# XMC4300 register map
Vendor: Infineon; File version: 0.5.1 (Superset device XMC4800)
CPU: CM4 r2p0, little endian, MPU, FPU, 6 interrupt priority bits
Registers are 32-bit, read-write, reset 0x0 unless marked. A register's access mark holds for its fields unless they carry their own. Offsets are from the block's base; [hi:lo] are bit positions; {n}, {i} and the like mark numbered series; 'fields as' and 'values as' point back to an identical list.

## SCU_POWER — System Control Unit
Base 0x50004200
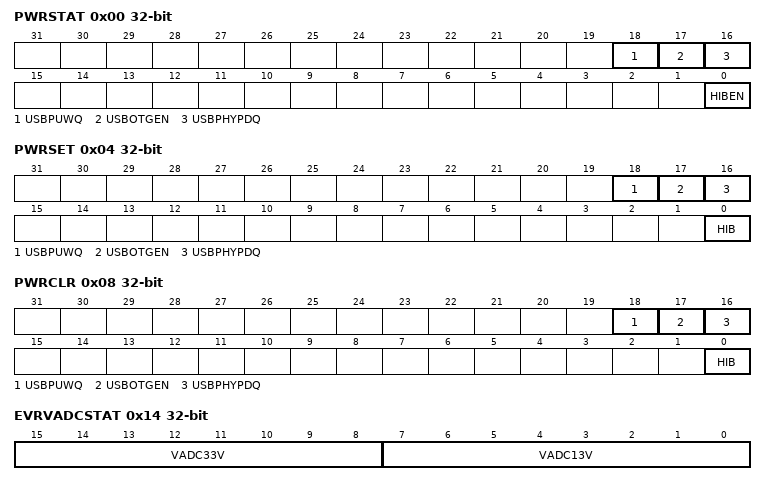
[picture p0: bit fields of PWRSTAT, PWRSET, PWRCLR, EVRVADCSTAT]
0x00 PWRSTAT ro — PCU Status Register
  [18] USBPUWQ — USB Weak Pull-Up at PADN State
    0=Pull-up active; 1=Pull-up not active
  [17] USBOTGEN — USB On-The-Go Comparators State
    0=Power-down; 1=Active
  [16] USBPHYPDQ — USB PHY Transceiver State
    0=Power-down; 1=Active
  [0] HIBEN — Hibernate Domain Enable Status
    0=Inactive; 1=Active
0x04 PWRSET wo — PCU Set Control Register
  [18] USBPUWQ — Set USB Weak Pull-Up at PADN Enable
    0=No effect; 1=Pull-up not active
  [17] USBOTGEN — Set USB On-The-Go Comparators Enable
    0=No effect; 1=Active
  [16] USBPHYPDQ — Set USB PHY Transceiver Disable
    0=No effect; 1=Active
  [0] HIB — Set Hibernate Domain Enable
    0=No effect; 1=Enable Hibernate domain
0x08 PWRCLR wo — PCU Clear Control Register
  [18] USBPUWQ — Clear USB Weak Pull-Up at PADN Enable
    0=No effect; 1=Pull-up active
  [17] USBOTGEN — Clear USB On-The-Go Comparators Enable
    0=No effect; 1=Power-down
  [16] USBPHYPDQ — Clear USB PHY Transceiver Disable
    0=No effect; 1=Power-down
  [0] HIB — Clear Disable Hibernate Domain
    0=No effect; 1=Disable Hibernate domain
0x10 EVRSTAT ro — EVR Status Register
  [1] OV13 — Regulator Overvoltage for 1.3 V
    0=No overvoltage condition; 1=Regulator is in overvoltage
0x14 EVRVADCSTAT ro — EVR VADC Status Register
  [15:8] VADC33V — VADC 3.3 V Conversion Result
  [7:0] VADC13V — VADC 1.3 V Conversion Result
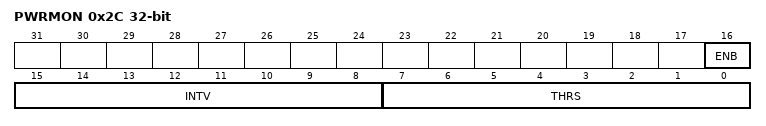
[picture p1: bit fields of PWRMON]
0x2C PWRMON — Power Monitor Control
  [16] ENB — Enable
  [15:8] INTV — Interval
  [7:0] THRS — Threshold

## SDMMC_CON — SD and Multimediacard Control Register
Base 0x500040B4
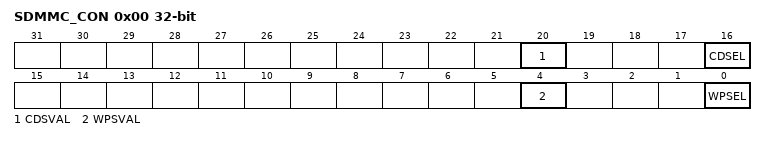
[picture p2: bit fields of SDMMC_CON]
0x00 SDMMC_CON — SDMMC Configuration
  [20] CDSVAL — SDMMC Write Protect Software Control
    0=No card detected; 1=Card detected
  [16] CDSEL — SDMMC Card Detection Control
    0=P1.10 input pin selected; 1=Software bit CDSVAL is selected
  [4] WPSVAL — SDMMC Write Protect Software Control
    0=No write protection; 1=Write protection active
  [0] WPSEL — SDMMC Write Protection Input Multiplexer Control
    0=P1.1 input pin selected; 1=Software bit WPVAL is selected

## ETH0_CON — Ethernet Control Register
Base 0x50004040
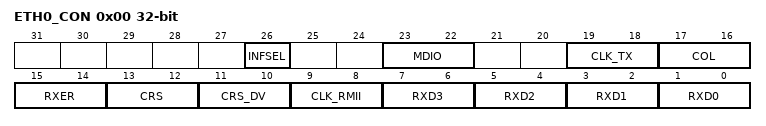
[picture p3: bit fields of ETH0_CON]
0x00 ETH0_CON — Ethernet 0 Port Control Register
  [26] INFSEL — Ethernet MAC Interface Selection
    0=MII; 1=RMII
  [23:22] MDIO — MDIO Input Select
    0=Data input MDIA is selected; 1=Data input MDIB is selected; 2=Data input MDIC is selected; 3=Data input MDID is selected
  [19:18] CLK_TX — CLK_TX input
    0=Data input CLK_TXA is selected; 1=Data input CLK_TXB is selected; 2=Data input CLK_TXC is selected; 3=Data input CLK_TXD is selected
  [17:16] COL — COL input
    0=Data input COLA is selected; 1=Data input COLB is selected; 2=Data input COLC is selected; 3=Data input COLD is selected
  [15:14] RXER — RXER Input
    0=Data input RXERA is selected; 1=Data input RXERB is selected; 2=Data input RXERC is selected; 3=Data input RXERD is selected
  [13:12] CRS — CRS input
    0=Data input CRSA; 1=Data input CRSB; 2=Data input CRSC; 3=Data input CRSD
  [11:10] CRS_DV — CRS_DV input
    0=Data input CRS_DVA is selected; 1=Data input CRS_DVB is selected; 2=Data input CRS_DVC is selected; 3=Data input CRS_DVD is selected
  [9:8] CLK_RMII — RMII clock input
    0=Data input RMIIA is selected; 1=Data input RMIIB is selected; 2=Data input RMIIC is selected; 3=Data input RMIID is selected
  [2n+1:2n] RXD{n} (n=0..3) — MAC Receive Input {n}
    0=Data input RXD{n}A is selected; 1=Data input RXD{n}B is selected; 2=Data input RXD{n}C is selected; 3=Data input RXD{n}D is selected

## ECAT0_CON — EtherCAT 0 Control Register
Base 0x500041B0
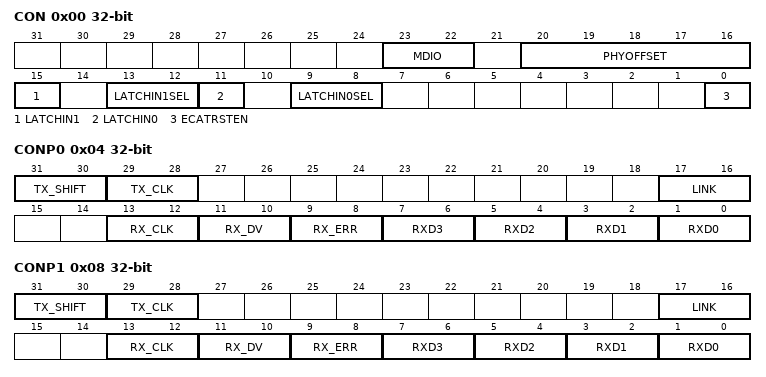
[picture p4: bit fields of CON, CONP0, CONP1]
0x00 CON access per field — EtherCAT 0 Control
  [23:22] MDIO rw — MDIO Input Select
    0=Data input MDIA is selected; 1=Data input MDIB is selected; 2=Data input MDIC is selected; 3=Data input MDID is selected
  [20:16] PHYOFFSET rw — Ethernet PHY Address Offset
  [15] LATCHIN1 ro — EtherCAT LATCH_IN1 Input Signal
  [13:12] LATCHIN1SEL rw — LATCHIN1 Input Select
    0=Data input LATCHIN1A is selected; 1=Data input LATCHIN1B is selected; 2=Data input LATCHIN1C is selected; 3=Data input LATCHIN1D is selected
  [11] LATCHIN0 ro — EtherCAT LATCH_IN0 Input Signal
  [9:8] LATCHIN0SEL rw — LATCHIN0 Input Select
    0=Data input LATCHIN0A is selected; 1=Data input LATCHIN0B is selected; 2=Data input LATCHIN0C is selected; 3=Data input LATCHIN0D is selected
  [0] ECATRSTEN rw — Enable EtherCAT Reset Request
    0=Reset request by EtherCAT Master disabled; 1=Reset request by EtherCAT Master enabled
0x04 CONP0 — EtherCAT 0 Port 1 Control Register
  [31:30] TX_SHIFT — Port0 Manual TX Shift configuration
    0=0 ns; 1=10 ns; 2=20 ns; 3=30 ns
  [29:28] TX_CLK — Port0 MII TX Clock Input Select
    0=Clock input TX_CLKA; 1=Clock input TX_CLKB; 2=Clock input TX_CLKC; 3=Clock input TX_CLKD
  [17:16] LINK — Port0 PHY Link Input Select
    0=PHY LINKA; 1=PHY LINKB; 2=PHY LINKC; 3=PHY LINKD
  [13:12] RX_CLK — Port0 MII RX Clock Input Select
    0=Clock input RX_CLKA; 1=Clock input RX_CLKB; 2=Clock input RX_CLKC; 3=Clock input RX_CLKD
  [11:10] RX_DV — Port0 MII RX DV Input Select
    0=Data input RX_DVA is selected; 1=Data input RX_DVB is selected; 2=Data input RX_DVC is selected; 3=Data input RX_DVD is selected
  [9:8] RX_ERR — Port0 MII RX ERROR Input Select
    0=Data input RX_ERRA is selected; 1=Data input RX_ERRB is selected; 2=Data input RX_ERRC is selected; 3=Data input RX_ERRD is selected
  [7:6] RXD3 — Port0 Receive Input 3 Select
    0=Data input RXD3A is selected; 1=Data input RXD3B is selected; 2=Data input RXD3C is selected; 3=Data input RXD3D is selected
  [5:4] RXD2 — Port0 Receive Input 2 Select
    0=Data input RXD2A is selected; 1=Data input RXD2B is selected; 2=Data input RXD2C is selected; 3=Data input RXD2D is selected
  [3:2] RXD1 — Port0 Receive Input 1 Select
    0=Data input RXD1A is selected; 1=Data input RXD1B is selected; 2=Data input RXD1C is selected; 3=Data input RXD1D is selected
  [1:0] RXD0 — PORT0 Receive Input 0 Select
    0=Data input RXD0A is selected; 1=Data input RXD0B is selected; 2=Data input RXD0C is selected; 3=Data input RXD0D is selected
0x08 CONP1 — EtherCAT 0 Port 1 Control Register
  [31:30] TX_SHIFT — Port1 Manual TX Shift configuration
    0=0 ns; 1=10 ns; 2=20 ns; 3=30 ns
  [29:28] TX_CLK — Port1 MII TX Clock Input Select
    values as CONP0.TX_CLK
  [17:16] LINK — Port1 PHY Link Input Select
    0=PHY LINKA; 1=PHY LINKB; 2=PHY LINKC; 3=PHY LINKD
  [13:12] RX_CLK — Port1 MII RX Clock Input Select
    values as CONP0.RX_CLK
  [11:10] RX_DV — Port1 MII RX DV Input Select
    values as CONP0.RX_DV
  [9:8] RX_ERR — Port1 MII RX ERROR Input Select
    values as CONP0.RX_ERR
  [2n+1:2n] RXD{n} (n=0..3) — Port1 Receive Input {n} Select
    0=Data input RXD{n}A is selected; 1=Data input RXD{n}B is selected; 2=Data input RXD{n}C is selected; 3=Data input RXD{n}D is selected
